AUTOSAR XML (schema 4-2-2)
package /ComponentTypes
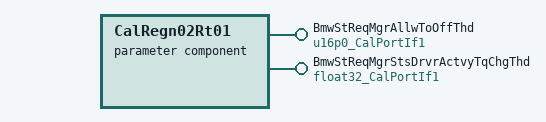
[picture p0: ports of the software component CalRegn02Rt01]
  parameter sw component type CalRegn02Rt01
    provide port BmwStReqMgrAllwToOffThd: parameter-provide-com-spec{init-value=500, parameter=Val}, provided-interface=u16p0_CalPortIf1
    provide port BmwStReqMgrStsDrvrActvyTqChgThd: parameter-provide-com-spec{init-value=0.2, parameter=Val}, provided-interface=float32_CalPortIf1
